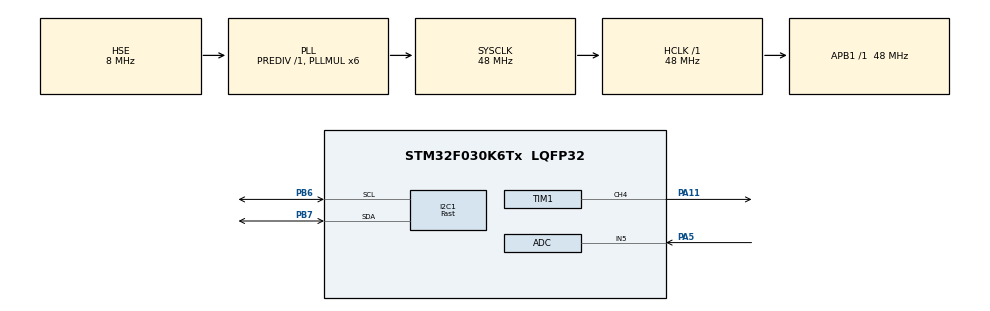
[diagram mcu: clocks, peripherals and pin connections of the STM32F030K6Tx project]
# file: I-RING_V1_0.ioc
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ADC.DiscontinuousConvMode=DISABLE
ADC.ScanConvMode=ADC_SCAN_DIRECTION_FORWARD
I2C1.I2C_Speed_Mode=I2C_Fast
I2C1.Timing=0x0000020B
Mcu.Family=STM32F0
Mcu.Name=STM32F030K6Tx
Mcu.Package=LQFP32
NVIC.TIM14_IRQn=true\:0\:0\:false\:false\:true\:true\:true\:true
PA11.Signal=S_TIM1_CH4
PA13.Mode=Serial_Wire
PA13.Signal=SYS_SWDIO
PA14.Mode=Serial_Wire
PA14.Signal=SYS_SWCLK
PA5.Mode=IN5
PA5.Signal=ADC_IN5
PB6.GPIO_Pu=GPIO_PULLUP
PB6.Mode=I2C
PB6.Signal=I2C1_SCL
PB7.GPIO_Pu=GPIO_PULLUP
PB7.Mode=I2C
PB7.Signal=I2C1_SDA
PF0-OSC_IN.Mode=HSE-External-Oscillator
PF0-OSC_IN.Signal=RCC_OSC_IN
PF1-OSC_OUT.Mode=HSE-External-Oscillator
PF1-OSC_OUT.Signal=RCC_OSC_OUT
ProjectManager.HeapSize=0x200
ProjectManager.StackSize=0x400
ProjectManager.TargetToolchain=MDK-ARM V5
RCC.AHBFreq_Value=48000000
RCC.APB1Freq_Value=48000000
RCC.APB1TimFreq_Value=48000000
RCC.HCLKFreq_Value=48000000
RCC.PLLMUL=RCC_PLL_MUL6
RCC.PLLSourceVirtual=RCC_PLLSOURCE_HSE
RCC.RTCClockSelection=RCC_RTCCLKSOURCE_HSE_DIV32
RCC.SYSCLKFreq_VALUE=48000000
RCC.SYSCLKSource=RCC_SYSCLKSOURCE_PLLCLK
RTC.AsynchPrediv=99
RTC.Date=5
RTC.Hours=16
RTC.Minutes=22
RTC.Month=RTC_MONTH_MARCH
RTC.Seconds=18
RTC.SynchPrediv=2499
RTC.WeekDay=RTC_WEEKDAY_SATURDAY
RTC.Year=22
SH.S_TIM1_CH4.0=TIM1_CH4,PWM Generation4 CH4
TIM1.Channel-PWM\ Generation4\ CH4=TIM_CHANNEL_4
TIM1.Period=10-1
TIM1.Prescaler=960-1
TIM1.Pulse-PWM\ Generation4\ CH4=5
TIM14.Period=10-1
TIM14.Prescaler=4800-1
VP_RTC_VS_RTC_Activate.Mode=RTC_Enabled
VP_RTC_VS_RTC_Calendar.Mode=RTC_Calendar
VP_TIM14_VS_ClockSourceINT.Mode=Enable_Timer
VP_TIM1_VS_ClockSourceINT.Mode=Internal
board=custom

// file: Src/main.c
/* USER CODE BEGIN Header */
/**
  ******************************************************************************
  * @author:LiangZai-Embedded
  * https://space.bilibili.com/432227375?spm_id_from=333.1007.0.0
  * https://github.com/LiangZai-Embedded
  ******************************************************************************
  * @attention
  *
  * <h2><center>&copy; Copyright (c) 2022 STMicroelectronics.
  * All rights reserved.</center></h2>
  *
  * This software component is licensed by ST under BSD 3-Clause license,
  * the "License"; You may not use this file except in compliance with the
  * License. You may obtain a copy of the License at:
  *                        opensource.org/licenses/BSD-3-Clause
  *
  ******************************************************************************
  */
/* USER CODE END Header */
#include "main.h"
#include "adc.h"
#include "i2c.h"
#include "rtc.h"
#include "tim.h"
#include "gpio.h"

void SystemClock_Config(void);

int main(void)
{
  /* USER CODE BEGIN 1 */
  Data data = {0};
  /* USER CODE END 1 */

  /* MCU Configuration--------------------------------------------------------*/

  /* Reset of all peripherals, Initializes the Flash interface and the Systick. */
  HAL_Init();

  /* Configure the system clock */
  SystemClock_Config();

  /* USER CODE BEGIN SysInit */
	HAL_Delay(500);
  /* USER CODE END SysInit */

  /* Initialize all configured peripherals */
  MX_GPIO_Init();
  MX_ADC_Init();
  MX_I2C1_Init();
  MX_RTC_Init();
  MX_TIM14_Init();
  MX_TIM1_Init();
  /* USER CODE BEGIN 2 */
	BEEP_ON();

	hmc5883l_init();
  icm20602_init();

  u8g2Init(&u8g2);
	biquad_filter_init();

	HAL_TIM_Base_Start_IT(&htim14); //1KHz

	BEEP_OFF();
  /* USER CODE END 2 */

  /* Infinite loop */
  while (1)
  {

    /* USER CODE BEGIN 3 */
	  data_get(&data);
		ui_main(data);

	}
  /* USER CODE END 3 */
}

void SystemClock_Config(void)
{
  RCC_OscInitTypeDef RCC_OscInitStruct = {0};
  RCC_ClkInitTypeDef RCC_ClkInitStruct = {0};
  RCC_PeriphCLKInitTypeDef PeriphClkInit = {0};

  /** Initializes the RCC Oscillators according to the specified parameters
  * in the RCC_OscInitTypeDef structure.
  */
  RCC_OscInitStruct.OscillatorType = RCC_OSCILLATORTYPE_HSI|RCC_OSCILLATORTYPE_HSI14
                              |RCC_OSCILLATORTYPE_HSE;
  RCC_OscInitStruct.HSEState = RCC_HSE_ON;
  RCC_OscInitStruct.HSIState = RCC_HSI_ON;
  RCC_OscInitStruct.HSI14State = RCC_HSI14_ON;
  RCC_OscInitStruct.HSICalibrationValue = RCC_HSICALIBRATION_DEFAULT;
  RCC_OscInitStruct.HSI14CalibrationValue = 16;
  RCC_OscInitStruct.PLL.PLLState = RCC_PLL_ON;
  RCC_OscInitStruct.PLL.PLLSource = RCC_PLLSOURCE_HSE;
  RCC_OscInitStruct.PLL.PLLMUL = RCC_PLL_MUL6;
  RCC_OscInitStruct.PLL.PREDIV = RCC_PREDIV_DIV1;
  if (HAL_RCC_OscConfig(&RCC_OscInitStruct) != HAL_OK)
  {
    Error_Handler();
  }

  /** Initializes the CPU, AHB and APB buses clocks
  */
  RCC_ClkInitStruct.ClockType = RCC_CLOCKTYPE_HCLK|RCC_CLOCKTYPE_SYSCLK
                              |RCC_CLOCKTYPE_PCLK1;
  RCC_ClkInitStruct.SYSCLKSource = RCC_SYSCLKSOURCE_PLLCLK;
  RCC_ClkInitStruct.AHBCLKDivider = RCC_SYSCLK_DIV1;
  RCC_ClkInitStruct.APB1CLKDivider = RCC_HCLK_DIV1;

  if (HAL_RCC_ClockConfig(&RCC_ClkInitStruct, FLASH_LATENCY_1) != HAL_OK)
  {
    Error_Handler();
  }
  PeriphClkInit.PeriphClockSelection = RCC_PERIPHCLK_I2C1|RCC_PERIPHCLK_RTC;
  PeriphClkInit.I2c1ClockSelection = RCC_I2C1CLKSOURCE_HSI;
  PeriphClkInit.RTCClockSelection = RCC_RTCCLKSOURCE_HSE_DIV32;
  if (HAL_RCCEx_PeriphCLKConfig(&PeriphClkInit) != HAL_OK)
  {
    Error_Handler();
  }
}

void Error_Handler(void)
{
}
